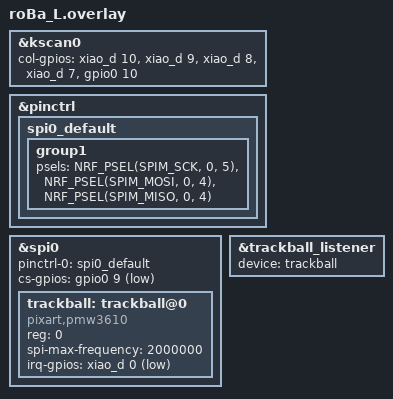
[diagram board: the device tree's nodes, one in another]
#include "roBa.dtsi"

&kscan0 {
    col-gpios
        = <&xiao_d 10 GPIO_ACTIVE_HIGH>
        , <&xiao_d 9 GPIO_ACTIVE_HIGH> 
        , <&xiao_d 8 GPIO_ACTIVE_HIGH> 
        , <&xiao_d 7 GPIO_ACTIVE_HIGH> 
        , <&gpio0 10 GPIO_ACTIVE_HIGH> // NFC2
        ;
};

// コンパイラが求めている、SPIの物理ピン（D5, D4）のグループ定義
&pinctrl {
    spi0_default: spi0_default {
        group1 {
            psels = <NRF_PSEL(SPIM_SCK, 0, 5)>,   // SCLK=D5
                    <NRF_PSEL(SPIM_MOSI, 0, 4)>,  // SDIO=D4
                    <NRF_PSEL(SPIM_MISO, 0, 4)>;  // SDIO=D4
        };
    };
};

&spi0 {
    status = "okay";
    pinctrl-0 = <&spi0_default>; // ★ここが不足していたため怒られていました！
    pinctrl-names = "default";   // ★ここが不足していたため怒られていました！
    cs-gpios = <&gpio0 9 GPIO_ACTIVE_LOW>; // CS=NFC1

    trackball: trackball@0 {
        compatible = "pixart,pmw3610";
        reg = <0>;
        spi-max-frequency = <2000000>;
        irq-gpios = <&xiao_d 0 (GPIO_ACTIVE_LOW | GPIO_PULL_UP)>; // MOTION=D0
    };
};

&trackball_listener {
    status = "okay";
    device = <&trackball>;
};
